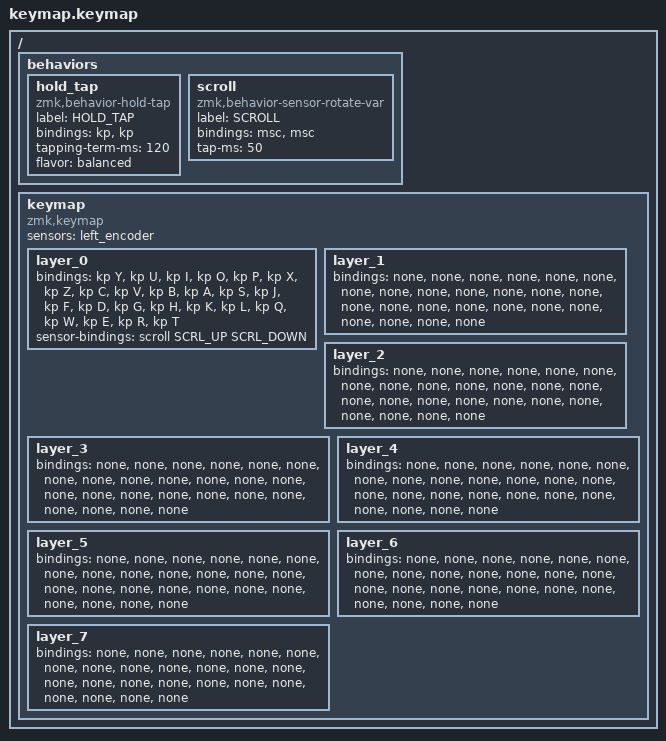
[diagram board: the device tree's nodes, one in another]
#define ZMK_POINTING_DEFAULT_SCRL_VAL 30

#include <behaviors.dtsi>
#include <dt-bindings/zmk/keys.h>
#include <dt-bindings/zmk/pointing.h>

/ {
    behaviors {
        hold_tap: hold_tap {
            compatible = "zmk,behavior-hold-tap";
            label = "HOLD_TAP";
            bindings = <&kp>, <&kp>;

            #binding-cells = <2>;
            tapping-term-ms = <120>;
            flavor = "balanced";
        };

        scroll: scroll {
            compatible = "zmk,behavior-sensor-rotate-var";
            label = "SCROLL";
            #sensor-binding-cells = <2>;
            bindings = <&msc>, <&msc>;

            tap-ms = <50>;
        };
    };

    keymap {
        compatible = "zmk,keymap";
        sensors = <&left_encoder>;

        layer_0 {
            bindings = <
&kp Y
&kp U
&kp I
&kp O
&kp P
&kp X
&kp Z
&kp C
&kp V
&kp B
&kp A
&kp S
&kp J
&kp F
&kp D
&kp G
&kp H
&kp K
&kp L
&kp Q
&kp W
&kp E
&kp R
&kp T
            >;

            sensor-bindings = <&scroll SCRL_UP SCRL_DOWN>;
        };

        layer_1 {
            bindings = <
&none
&none
&none
&none
&none
&none
&none
&none
&none
&none
&none
&none
&none
&none
&none
&none
&none
&none
&none
&none
&none
&none
&none
&none
            >;
        };

        layer_2 {
            bindings = <
&none
&none
&none
&none
&none
&none
&none
&none
&none
&none
&none
&none
&none
&none
&none
&none
&none
&none
&none
&none
&none
&none
&none
&none
            >;
        };

        layer_3 {
            bindings = <
&none
&none
&none
&none
&none
&none
&none
&none
&none
&none
&none
&none
&none
&none
&none
&none
&none
&none
&none
&none
&none
&none
&none
&none
            >;
        };

        layer_4 {
            bindings = <
&none
&none
&none
&none
&none
&none
&none
&none
&none
&none
&none
&none
&none
&none
&none
&none
&none
&none
&none
&none
&none
&none
&none
&none
            >;
        };

        layer_5 {
            bindings = <
&none
&none
&none
&none
&none
&none
&none
&none
&none
&none
&none
&none
&none
&none
&none
&none
&none
&none
&none
&none
&none
&none
&none
&none
            >;
        };

        layer_6 {
            bindings = <
&none
&none
&none
&none
&none
&none
&none
&none
&none
&none
&none
&none
&none
&none
&none
&none
&none
&none
&none
&none
&none
&none
&none
&none
            >;
        };

        layer_7 {
            bindings = <
&none
&none
&none
&none
&none
&none
&none
&none
&none
&none
&none
&none
&none
&none
&none
&none
&none
&none
&none
&none
&none
&none
&none
&none
            >;
        };
    };
};
